# ATSAMD11D1xAx register map
Vendor: Atmel Corporation; Series: SAMD11; File version: A
CPU: CM0+ r0p1, little endian, no MPU, no FPU, VTOR, 2 interrupt priority bits
Registers are 8-bit, read-write, reset 0x0 unless marked. A register's access mark holds for its fields unless they carry their own. Offsets are from the block's base; [hi:lo] are bit positions; {n}, {i} and the like mark numbered series; 'fields as' and 'values as' point back to an identical list.

## TCC0 — Timer Counter Control
Base 0x42001400; register names take the prefix TCC_
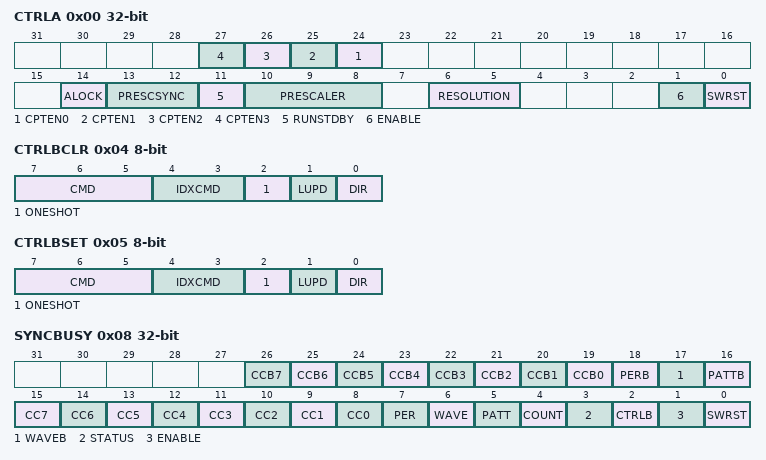
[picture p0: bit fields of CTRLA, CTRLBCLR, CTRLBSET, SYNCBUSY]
0x00 CTRLA 32-bit — Control A
  [n+24] CPTEN{n} (n=0..3) — Capture Channel {n} Enable
  [14] ALOCK — Auto Lock
  [13:12] PRESCSYNC — Prescaler and Counter Synchronization Selection
    0=GCLK; 1=PRESC; 2=RESYNC
  [11] RUNSTDBY — Run in Standby
  [10:8] PRESCALER
    0=DIV1; 1=DIV2; 2=DIV4; 3=DIV8; 4=DIV16; 5=DIV64; 6=DIV256; 7=DIV1024
  [6:5] RESOLUTION — Enhanced Resolution
    0=None; 1=DITH4; 2=DITH5; 3=DITH6
  [1] ENABLE
  [0] SWRST — Software Reset
0x04 CTRLBCLR — Control B Clear
  [7:5] CMD — TCC Command
    0=NONE; 1=RETRIGGER; 2=STOP; 3=UPDATE; 4=READSYNC
  [4:3] IDXCMD — Ramp Index Command
    0=DISABLE; 1=SET; 2=CLEAR; 3=HOLD
  [2] ONESHOT
  [1] LUPD — Lock Update
  [0] DIR — Counter Direction
0x05 CTRLBSET — Control B Set
  [7:5] CMD — TCC Command
    0=NONE; 1=RETRIGGER; 2=STOP; 3=UPDATE; 4=READSYNC
  [4:3] IDXCMD — Ramp Index Command
    0=DISABLE; 1=SET; 2=CLEAR; 3=HOLD
  [2] ONESHOT
  [1] LUPD — Lock update
  [0] DIR — Counter Direction
0x08 SYNCBUSY 32-bit ro — Synchronization Busy
  [n+19] CCB{n} (n=0..7) — Compare Channel Buffer {n} Busy
  [18] PERB — Period Buffer Busy
  [17] WAVEB — Wave Buffer Busy
  [16] PATTB — Pattern Buffer Busy
  [n+8] CC{n} (n=0..7) — Compare Channel Buffer {n} Busy
  [7] PER — Period busy
  [6] WAVE — wave Busy
  [5] PATT — Pattern Busy
  [4] COUNT — Count Busy
  [3] STATUS — Status Busy
  [2] CTRLB — Ctrlb Busy
  [1] ENABLE — Enable Busy
  [0] SWRST — Swrst Busy
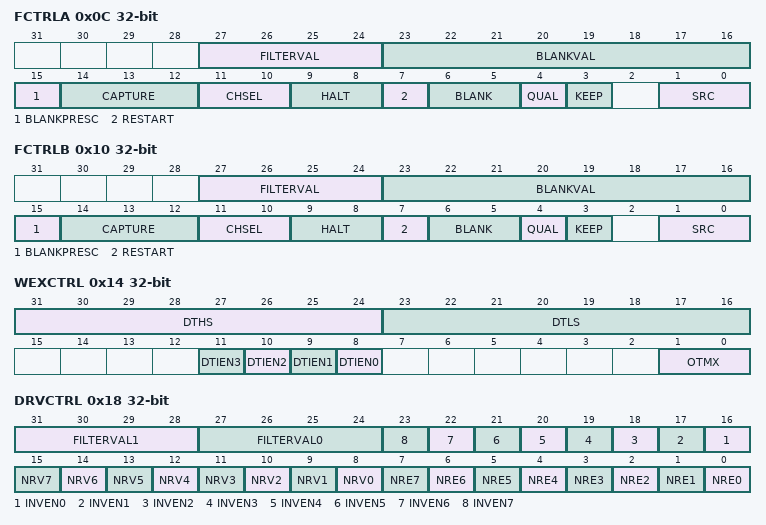
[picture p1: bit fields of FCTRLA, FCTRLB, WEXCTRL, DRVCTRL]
0x0C FCTRLA 32-bit — Recoverable FaultA Configuration
  [27:24] FILTERVAL — FaultA Filter Value
  [23:16] BLANKVAL — FaultA Blanking Time
  [15] BLANKPRESC — FaultA Blanking Prescalar
  [14:12] CAPTURE — FaultA Capture Action
    0=DISABLE; 1=CAPT; 2=CAPTMIN; 3=CAPTMAX; 4=LOCMIN; 5=LOCMAX; 6=DERIV0; 7=CAPTMARK
  [11:10] CHSEL — FaultA Capture Channel
    {v}=CC{v} (v=0..3)
  [9:8] HALT — FaultA Halt Mode
    0=DISABLE; 1=HW; 2=SW; 3=NR
  [7] RESTART — FaultA Restart
  [6:5] BLANK — FaultA Blanking Mode
    0=START; 1=RISE; 2=FALL; 3=BOTH
  [4] QUAL — FaultA Qualification
  [3] KEEP — FaultA Keeper
  [1:0] SRC — FaultA Source
    0=DISABLE; 1=ENABLE; 2=INVERT; 3=ALTFAULT
0x10 FCTRLB 32-bit — Recoverable FaultB Configuration
  [27:24] FILTERVAL — FaultB Filter Value
  [23:16] BLANKVAL — FaultB Blanking Time
  [15] BLANKPRESC — FaultB Blanking Prescalar
  [14:12] CAPTURE — FaultB Capture Action
    values as FCTRLA.CAPTURE
  [11:10] CHSEL — FaultB Capture Channel
    {v}=CC{v} (v=0..3)
  [9:8] HALT — FaultB Halt Mode
    0=DISABLE; 1=HW; 2=SW; 3=NR
  [7] RESTART — FaultB Restart
  [6:5] BLANK — FaultB Blanking Mode
    0=START; 1=RISE; 2=FALL; 3=BOTH
  [4] QUAL — FaultB Qualification
  [3] KEEP — FaultB Keeper
  [1:0] SRC — FaultB Source
    0=DISABLE; 1=ENABLE; 2=INVERT; 3=ALTFAULT
0x14 WEXCTRL 32-bit — Waveform Extension Configuration
  [31:24] DTHS — Dead-time High Side Outputs Value
  [23:16] DTLS — Dead-time Low Side Outputs Value
  [n+8] DTIEN{n} (n=0..3) — Dead-time Insertion Generator {n} Enable
  [1:0] OTMX — Output Matrix
0x18 DRVCTRL 32-bit — Driver Configuration
  [31:28] FILTERVAL1 — Non-Recoverable Fault Input 1 Filter Value
  [27:24] FILTERVAL0 — Non-Recoverable Fault Input 0 Filter Value
  [n+16] INVEN{n} (n=0..7) — Output Waveform {n} Inversion
  [n+8] NRV{n} (n=0..7) — Non-Recoverable State {n} Output Value
  [n] NRE{n} (n=0..7) — Non-Recoverable State {n} Output Enable
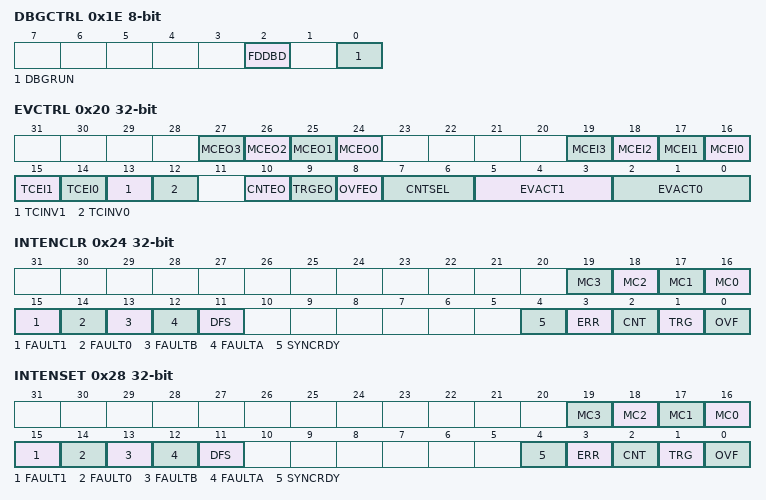
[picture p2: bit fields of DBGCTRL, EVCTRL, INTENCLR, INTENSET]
0x1E DBGCTRL — Debug Control
  [2] FDDBD — Fault Detection on Debug Break Detection
  [0] DBGRUN — Debug Running Mode
0x20 EVCTRL 32-bit — Event Control
  [n+24] MCEO{n} (n=0..3) — Match or Capture Channel {n} Event Output Enable
  [n+16] MCEI{n} (n=0..3) — Match or Capture Channel {n} Event Input Enable
  [15] TCEI1 — Timer/counter Event 1 Input Enable
  [14] TCEI0 — Timer/counter Event 0 Input Enable
  [13] TCINV1 — Inverted Event 1 Input Enable
  [12] TCINV0 — Inverted Event 0 Input Enable
  [10] CNTEO — Timer/counter Output Event Enable
  [9] TRGEO — Retrigger Output Event Enable
  [8] OVFEO — Overflow/Underflow Output Event Enable
  [7:6] CNTSEL — Timer/counter Output Event Mode
    0=START; 1=END; 2=BETWEEN; 3=BOUNDARY
  [5:3] EVACT1 — Timer/counter Input Event1 Action
    0=OFF; 1=RETRIGGER; 2=DIR; 3=STOP; 4=DEC; 5=PPW; 6=PWP; 7=FAULT
  [2:0] EVACT0 — Timer/counter Input Event0 Action
    0=OFF; 1=RETRIGGER; 2=COUNTEV; 3=START; 4=INC; 5=COUNT; 7=FAULT
0x24 INTENCLR 32-bit — Interrupt Enable Clear
  [n+16] MC{n} (n=0..3) — Match or Capture Channel {n} Interrupt Enable
  [15] FAULT1 — Non-Recoverable Fault 1 Interrupt Enable
  [14] FAULT0 — Non-Recoverable Fault 0 Interrupt Enable
  [13] FAULTB — Recoverable FaultB Interrupt Enable
  [12] FAULTA — Recoverable FaultA Interrupt Enable
  [11] DFS — Non-recoverable Debug Fault Interrupt Enable
  [4] SYNCRDY — Synchro Ready Interrupt Enable
  [3] ERR — Error Interrupt Enable
  [2] CNT — Counter Interrupt Enable
  [1] TRG — Retrigger Interrupt Enable
  [0] OVF — Overflow Interrupt Enable
0x28 INTENSET 32-bit — Interrupt Enable Set
  [n+16] MC{n} (n=0..3) — Match or Capture Channel {n} Interrupt Enable
  [15] FAULT1 — Non-Recoverable Fault 1 Interrupt Enabl
  [14] FAULT0 — Non-Recoverable Fault 0 Interrupt Enable
  [13] FAULTB — Recoverable FaultB Interrupt Enable
  [12] FAULTA — Recoverable FaultA Interrupt Enable
  [11] DFS — Non-Recoverable Debug Fault Interrupt Enable
  [4] SYNCRDY — Synchro Ready Interrupt Enable
  [3] ERR — Error Interrupt Enable
  [2] CNT — Counter Interrupt Enable
  [1] TRG — Retrigger Interrupt Enable
  [0] OVF — Overflow Interrupt Enable
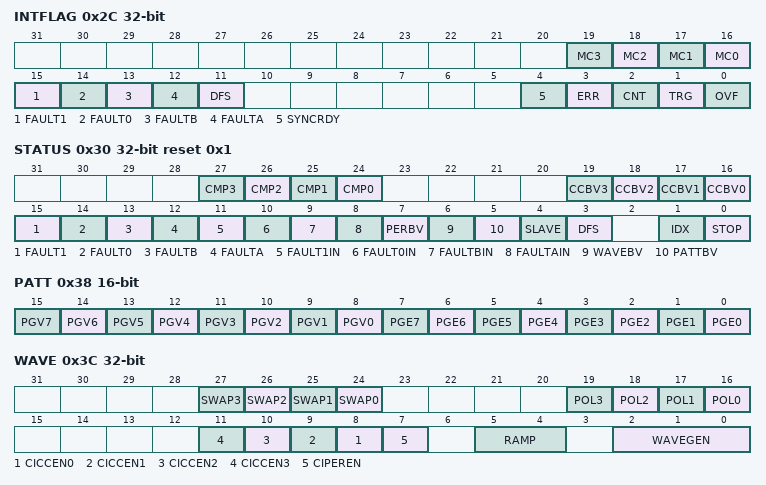
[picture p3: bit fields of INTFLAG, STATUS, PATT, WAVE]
0x2C INTFLAG 32-bit — Interrupt Flag Status and Clear
  [n+16] MC{n} (n=0..3) — Match or Capture {n}
  [15] FAULT1 — Non-Recoverable Fault 1
  [14] FAULT0 — Non-Recoverable Fault 0
  [13] FAULTB — Recoverable FaultB
  [12] FAULTA — Recoverable FaultA
  [11] DFS — Non-Recoverable Debug Fault
  [4] SYNCRDY — Synchro Ready
  [3] ERR — Error
  [2] CNT — Counter
  [1] TRG — Retrigger
  [0] OVF — Overflow
0x30 STATUS 32-bit reset 0x1
  [n+24] CMP{n} ro (n=0..3) — Compare Channel {n} Value
  [n+16] CCBV{n} (n=0..3) — Compare Channel {n} Buffer Valid
  [15] FAULT1 — Non-Recoverable Fault 1 State
  [14] FAULT0 — Non-Recoverable Fault 0 State
  [13] FAULTB — Recoverable FaultB State
  [12] FAULTA — Recoverable FaultA State
  [11] FAULT1IN ro — Non-Recoverable Fault1 Input
  [10] FAULT0IN ro — Non-Recoverable Fault0 Input
  [9] FAULTBIN ro — Recoverable FaultB Input
  [8] FAULTAIN ro — Recoverable FaultA Input
  [7] PERBV — Period Buffer Valid
  [6] WAVEBV — Wave Buffer Valid
  [5] PATTBV — Pattern Buffer Valid
  [4] SLAVE ro
  [3] DFS — Non-Recoverable Debug Fault State
  [1] IDX ro — Ramp
  [0] STOP ro
0x34 COUNT 32-bit
  [23:0] COUNT — Count Value
0x38 PATT 16-bit — Pattern
  [n+8] PGV{n} (n=0..7) — Pattern Generator {n} Output Value
  [n] PGE{n} (n=0..7) — Pattern Generator {n} Output Enable
0x3C WAVE 32-bit — Waveform Control
  [n+24] SWAP{n} (n=0..3) — Swap DTI Output Pair {n}
  [n+16] POL{n} (n=0..3) — Channel {n} Polarity
  [n+8] CICCEN{n} (n=0..3) — Circular Channel {n} Enable
  [7] CIPEREN — Circular period Enable
  [5:4] RAMP — Ramp Mode
    0=RAMP1; 1=RAMP2A; 2=RAMP2; 3=RAMP2S
  [2:0] WAVEGEN — Waveform Generation
    0=NFRQ; 1=MFRQ; 2=NPWM; 4=DSCRITICAL; 5=DSBOTTOM; 6=DSBOTH; 7=DSTOP
0x40 PER 32-bit reset 0xFFFFFFFF — Period
  [23:0] PERIOD — Period Value
{0x44+4i} CC{i} (i=0..3) 32-bit — Compare and Capture
  [23:0] COUNT — Count Value
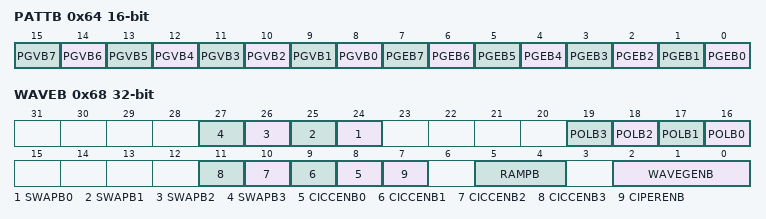
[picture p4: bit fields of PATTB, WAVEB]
0x64 PATTB 16-bit — Pattern Buffer
  [n+8] PGVB{n} (n=0..7) — Pattern Generator {n} Output Enable
  [n] PGEB{n} (n=0..7) — Pattern Generator {n} Output Enable Buffer
0x68 WAVEB 32-bit — Waveform Control Buffer
  [n+24] SWAPB{n} (n=0..3) — Swap DTI Output Pair {n} Buffer
  [n+16] POLB{n} (n=0..3) — Channel {n} Polarity Buffer
  [n+8] CICCENB{n} (n=0..3) — Circular Channel {n} Enable Buffer
  [7] CIPERENB — Circular Period Enable Buffer
  [5:4] RAMPB — Ramp Mode Buffer
  [2:0] WAVEGENB — Waveform Generation Buffer
    values as WAVE.WAVEGEN
0x6C PERB 32-bit reset 0xFFFFFFFF — Period Buffer
  [23:0] PERIOD — Period Value
{0x70+4i} CCB{i} (i=0..3) 32-bit — Compare and Capture Buffer
  [23:0] COUNT — Count Value

## Notices in the file
Atmel Microcontroller Software Support
Copyright (c) 2014, Atmel Corporation
All rights reserved.
Redistribution and use in source and binary forms, with or without
modification, are permitted provided that the following condition is met:
- Redistributions of source code must retain the above copyright notice,
this list of conditions and the disclaimer below.
Atmel's name may not be used to endorse or promote products derived from
this software without specific prior written permission.
DISCLAIMER: THIS SOFTWARE IS PROVIDED BY ATMEL "AS IS" AND ANY EXPRESS OR
IMPLIED WARRANTIES, INCLUDING, BUT NOT LIMITED TO, THE IMPLIED WARRANTIES OF
MERCHANTABILITY, FITNESS FOR A PARTICULAR PURPOSE AND NON-INFRINGEMENT ARE
DISCLAIMED. IN NO EVENT SHALL ATMEL BE LIABLE FOR ANY DIRECT, INDIRECT,
INCIDENTAL, SPECIAL, EXEMPLARY, OR CONSEQUENTIAL DAMAGES (INCLUDING, BUT NOT
LIMITED TO, PROCUREMENT OF SUBSTITUTE GOODS OR SERVICES; LOSS OF USE, DATA,
OR PROFITS; OR BUSINESS INTERRUPTION) HOWEVER CAUSED AND ON ANY THEORY OF
LIABILITY, WHETHER IN CONTRACT, STRICT LIABILITY, OR TORT (INCLUDING
NEGLIGENCE OR OTHERWISE) ARISING IN ANY WAY OUT OF THE USE OF THIS SOFTWARE,
EVEN IF ADVISED OF THE POSSIBILITY OF SUCH DAMAGE.
